VERSION ""

NS_ :

BS_:

BU_: HVC INV MOBO RPI SET VCU

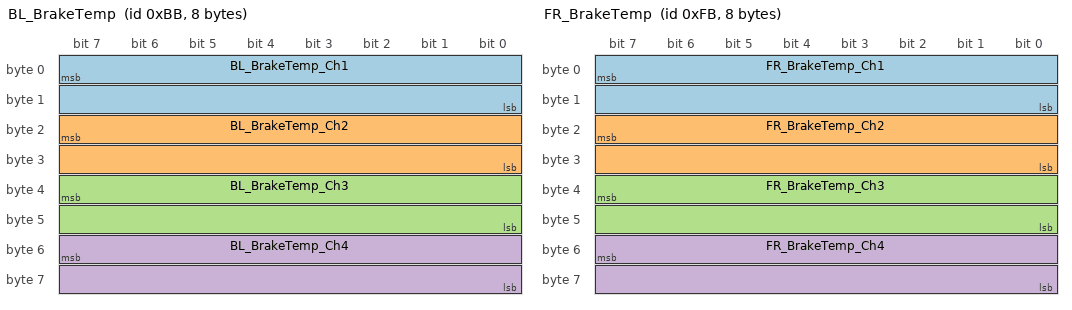
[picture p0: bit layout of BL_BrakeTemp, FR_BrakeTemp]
BO_ 187 BL_BrakeTemp: 8 BL
 SG_ BL_BrakeTemp_Ch1 : 7|16@0+ (0.1,-100.0) [-1000.0|1000.0] "C" Vector__XXX
 SG_ BL_BrakeTemp_Ch2 : 23|16@0+ (0.1,-100.0) [-1000.0|1000.0] "C" Vector__XXX
 SG_ BL_BrakeTemp_Ch3 : 39|16@0+ (0.1,-100.0) [-1000.0|1000.0] "C" Vector__XXX
 SG_ BL_BrakeTemp_Ch4 : 55|16@0+ (0.1,-100.0) [-1000.0|1000.0] "C" Vector__XXX

BO_ 251 FR_BrakeTemp: 8 FR
 SG_ FR_BrakeTemp_Ch1 : 7|16@0+ (0.1,-100.0) [-1000.0|1000.0] "C" Vector__XXX
 SG_ FR_BrakeTemp_Ch2 : 23|16@0+ (0.1,-100.0) [-1000.0|1000.0] "C" Vector__XXX
 SG_ FR_BrakeTemp_Ch3 : 39|16@0+ (0.1,-100.0) [-1000.0|1000.0] "C" Vector__XXX
 SG_ FR_BrakeTemp_Ch4 : 55|16@0+ (0.1,-100.0) [-1000.0|1000.0] "C" Vector__XXX

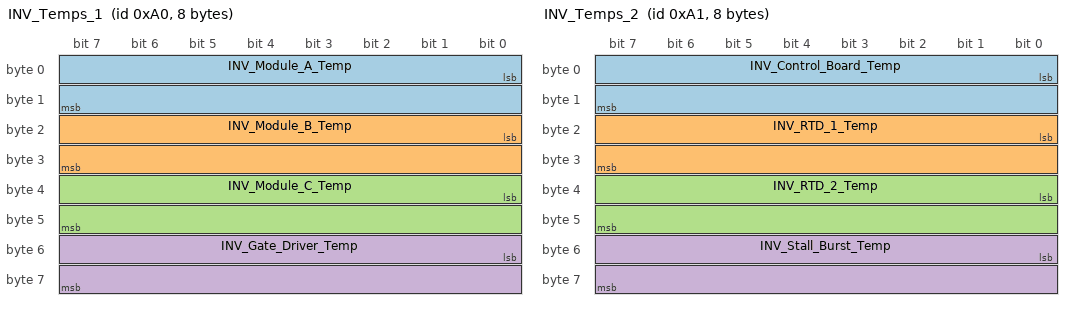
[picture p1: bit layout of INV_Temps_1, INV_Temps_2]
BO_ 160 INV_Temps_1: 8 INV
 SG_ INV_Module_A_Temp : 0|16@1- (0.1,0.0) [-1000.0|1000.0] "C" Vector__XXX
 SG_ INV_Module_B_Temp : 16|16@1- (0.1,0.0) [-1000.0|1000.0] "C" Vector__XXX
 SG_ INV_Module_C_Temp : 32|16@1- (0.1,0.0) [-1000.0|1000.0] "C" Vector__XXX
 SG_ INV_Gate_Driver_Temp : 48|16@1- (0.1,0.0) [-1000.0|1000.0] "C" Vector__XXX

BO_ 161 INV_Temps_2: 8 INV
 SG_ INV_Control_Board_Temp : 0|16@1- (0.1,0.0) [-1000.0|1000.0] "C" Vector__XXX
 SG_ INV_RTD_1_Temp : 16|16@1- (0.1,0.0) [-1000.0|1000.0] "C" Vector__XXX
 SG_ INV_RTD_2_Temp : 32|16@1- (0.1,0.0) [-1000.0|1000.0] "C" Vector__XXX
 SG_ INV_Stall_Burst_Temp : 48|16@1- (0.1,0.0) [-1000.0|1000.0] "C" Vector__XXX

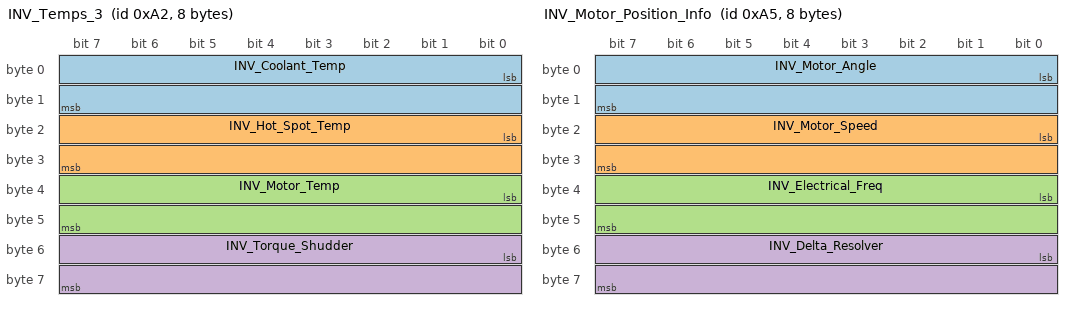
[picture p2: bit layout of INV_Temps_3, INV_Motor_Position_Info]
BO_ 162 INV_Temps_3: 8 INV
 SG_ INV_Coolant_Temp : 0|16@1- (0.1,0.0) [-1000.0|1000.0] "C" Vector__XXX
 SG_ INV_Hot_Spot_Temp : 16|16@1- (0.1,0.0) [-1000.0|1000.0] "C" Vector__XXX
 SG_ INV_Motor_Temp : 32|16@1- (0.1,0.0) [-1000.0|1000.0] "C" Vector__XXX
 SG_ INV_Torque_Shudder : 48|16@1- (0.1,0.0) [-230.0|230.0] "Nm" Vector__XXX

BO_ 165 INV_Motor_Position_Info: 8 INV
 SG_ INV_Motor_Angle : 0|16@1- (0.1,0.0) [-360.0|360.0] "deg" Vector__XXX
 SG_ INV_Motor_Speed : 16|16@1- (1.0,0.0) [-6000.0|6000.0] "RPM" Vector__XXX
 SG_ INV_Electrical_Freq : 32|16@1- (0.1,0.0) [-30000.0|30000.0] "Hz" Vector__XXX
 SG_ INV_Delta_Resolver : 48|16@1- (0.1,0.0) [-360.0|360.0] "deg" Vector__XXX

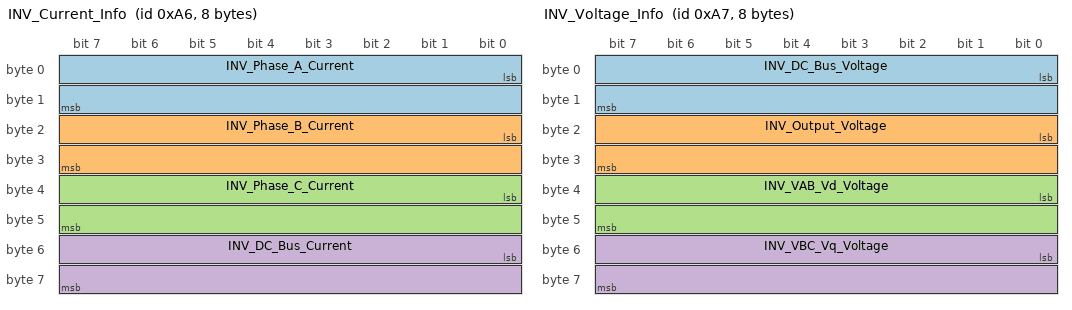
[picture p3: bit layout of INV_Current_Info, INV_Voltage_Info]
BO_ 166 INV_Current_Info: 8 INV
 SG_ INV_Phase_A_Current : 0|16@1- (0.1,0.0) [-1000.0|1000.0] "A" Vector__XXX
 SG_ INV_Phase_B_Current : 16|16@1- (0.1,0.0) [-1000.0|1000.0] "A" Vector__XXX
 SG_ INV_Phase_C_Current : 32|16@1- (0.1,0.0) [-1000.0|1000.0] "A" Vector__XXX
 SG_ INV_DC_Bus_Current : 48|16@1- (0.1,0.0) [-1000.0|1000.0] "A" Vector__XXX

BO_ 167 INV_Voltage_Info: 8 INV
 SG_ INV_DC_Bus_Voltage : 0|16@1- (0.1,0.0) [-1000.0|1000.0] "V" Vector__XXX
 SG_ INV_Output_Voltage : 16|16@1- (0.1,0.0) [-1000.0|1000.0] "V" Vector__XXX
 SG_ INV_VAB_Vd_Voltage : 32|16@1- (0.1,0.0) [-1000.0|1000.0] "V" Vector__XXX
 SG_ INV_VBC_Vq_Voltage : 48|16@1- (0.1,0.0) [-1000.0|1000.0] "V" Vector__XXX

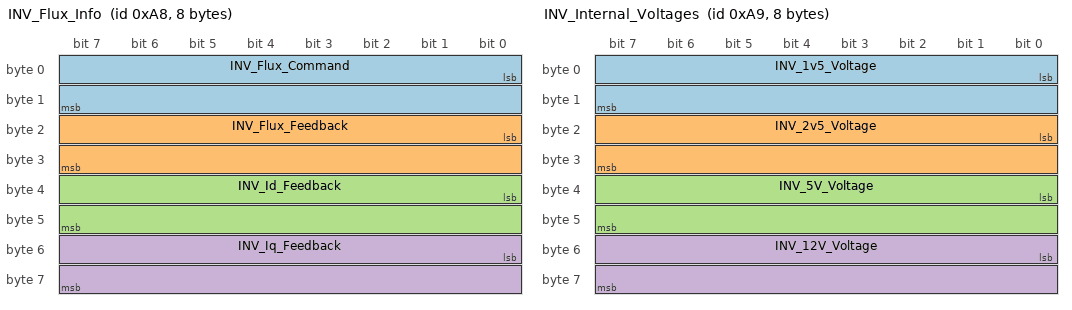
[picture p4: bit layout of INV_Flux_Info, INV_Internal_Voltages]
BO_ 168 INV_Flux_Info: 8 INV
 SG_ INV_Flux_Command : 0|16@1- (0.001,0.0) [-32.0|32.0] "Webers" Vector__XXX
 SG_ INV_Flux_Feedback : 16|16@1- (0.001,0.0) [-32.0|32.0] "Webers" Vector__XXX
 SG_ INV_Id_Feedback : 32|16@1- (0.1,0.0) [-1000.0|1000.0] "A" Vector__XXX
 SG_ INV_Iq_Feedback : 48|16@1- (0.1,0.0) [-1000.0|1000.0] "A" Vector__XXX

BO_ 169 INV_Internal_Voltages: 8 INV
 SG_ INV_1v5_Voltage : 0|16@1- (0.01,0.0) [-1000.0|1000.0] "V" Vector__XXX
 SG_ INV_2v5_Voltage : 16|16@1- (0.01,0.0) [-1000.0|1000.0] "V" Vector__XXX
 SG_ INV_5V_Voltage : 32|16@1- (0.01,0.0) [-1000.0|1000.0] "V" Vector__XXX
 SG_ INV_12V_Voltage : 48|16@1- (0.01,0.0) [-1000.0|1000.0] "V" Vector__XXX

BO_ 171 INV_Fault_Codes: 8 INV
 SG_ INV_Post_Fault_Lo : 0|16@1+ (1.0,0.0) [0.0|65535.0] "" Vector__XXX
 SG_ INV_Post_Fault_Hi : 16|16@1+ (1.0,0.0) [0.0|65535.0] "" Vector__XXX
 SG_ INV_Fault_Motor_Overspeed : 32|1@1+ (1.0,0.0) [0.0|1.0] "" Vector__XXX
 SG_ INV_Fault_Overcurrent : 33|1@1+ (1.0,0.0) [0.0|1.0] "" Vector__XXX
 SG_ INV_Fault_Overvoltage : 34|1@1+ (1.0,0.0) [0.0|1.0] "" Vector__XXX
 SG_ INV_Fault_Inverter_Overtemp : 35|1@1+ (1.0,0.0) [0.0|1.0] "" Vector__XXX
 SG_ INV_Fault_Accel_Input_Shorted : 36|1@1+ (1.0,0.0) [0.0|1.0] "" Vector__XXX
 SG_ INV_Fault_Accel_Input_Open : 37|1@1+ (1.0,0.0) [0.0|1.0] "" Vector__XXX
 SG_ INV_Fault_Direction_Cmd : 38|1@1+ (1.0,0.0) [0.0|1.0] "" Vector__XXX
 SG_ INV_Fault_Response_Timeout : 39|1@1+ (1.0,0.0) [0.0|1.0] "" Vector__XXX
 SG_ INV_Fault_HW_Gate : 40|1@1+ (1.0,0.0) [0.0|1.0] "" Vector__XXX
 SG_ INV_Fault_HW_Overcurrent : 41|1@1+ (1.0,0.0) [0.0|1.0] "" Vector__XXX
 SG_ INV_Fault_Undervoltage : 42|1@1+ (1.0,0.0) [0.0|1.0] "" Vector__XXX
 SG_ INV_Fault_Cmd_Msg_Lost : 43|1@1+ (1.0,0.0) [0.0|1.0] "" Vector__XXX
 SG_ INV_Fault_Motor_Overtemp : 44|1@1+ (1.0,0.0) [0.0|1.0] "" Vector__XXX
 SG_ INV_Fault_Brake_Input_Shorted : 48|1@1+ (1.0,0.0) [0.0|1.0] "" Vector__XXX
 SG_ INV_Fault_Brake_Input_Open : 49|1@1+ (1.0,0.0) [0.0|1.0] "" Vector__XXX
 SG_ INV_Fault_Module_A_Overtemp : 50|1@1+ (1.0,0.0) [0.0|1.0] "" Vector__XXX
 SG_ INV_Fault_Module_B_Overtemp : 51|1@1+ (1.0,0.0) [0.0|1.0] "" Vector__XXX
 SG_ INV_Fault_Module_C_Overtemp : 52|1@1+ (1.0,0.0) [0.0|1.0] "" Vector__XXX
 SG_ INV_Fault_PCB_Overtemp : 53|1@1+ (1.0,0.0) [0.0|1.0] "" Vector__XXX
 SG_ INV_Fault_Board_1_Overtemp : 54|1@1+ (1.0,0.0) [0.0|1.0] "" Vector__XXX
 SG_ INV_Fault_Board_2_Overtemp : 55|1@1+ (1.0,0.0) [0.0|1.0] "" Vector__XXX
 SG_ INV_Fault_Board_3_Overtemp : 56|1@1+ (1.0,0.0) [0.0|1.0] "" Vector__XXX
 SG_ INV_Fault_Curr_Sensor_Fault : 57|1@1+ (1.0,0.0) [0.0|1.0] "" Vector__XXX
 SG_ INV_Fault_Gate_Overvoltage : 58|1@1+ (1.0,0.0) [0.0|1.0] "" Vector__XXX
 SG_ INV_Fault_DC_Bus_Overvoltage : 60|1@1+ (1.0,0.0) [0.0|1.0] "" Vector__XXX
 SG_ INV_Fault_Resolver_Not_Cnctd : 62|1@1+ (1.0,0.0) [0.0|1.0] "" Vector__XXX

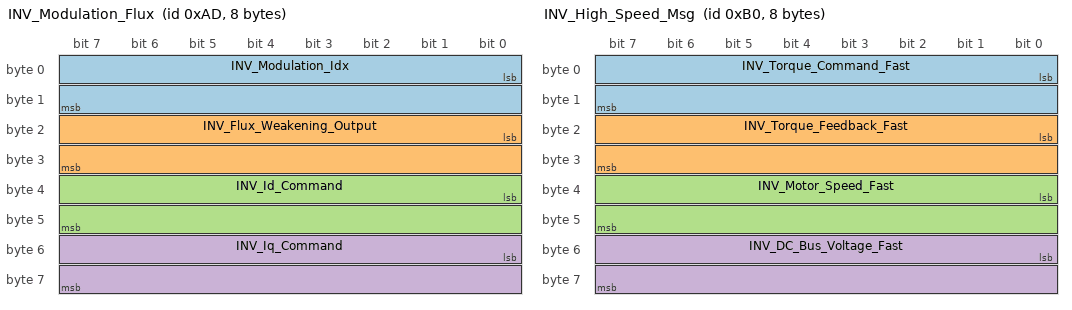
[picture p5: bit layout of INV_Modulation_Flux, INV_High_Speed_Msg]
BO_ 173 INV_Modulation_Flux: 8 INV
 SG_ INV_Modulation_Idx : 0|16@1+ (1.0,0.0) [0.0|65535.0] "" Vector__XXX
 SG_ INV_Flux_Weakening_Output : 16|16@1- (0.1,0.0) [-1000.0|1000.0] "A" Vector__XXX
 SG_ INV_Id_Command : 32|16@1- (0.1,0.0) [-1000.0|1000.0] "A" Vector__XXX
 SG_ INV_Iq_Command : 48|16@1- (0.1,0.0) [-1000.0|1000.0] "A" Vector__XXX

BO_ 176 INV_High_Speed_Msg: 8 INV
 SG_ INV_Torque_Command_Fast : 0|16@1- (0.1,0.0) [-230.0|230.0] "Nm" Vector__XXX
 SG_ INV_Torque_Feedback_Fast : 16|16@1- (0.1,0.0) [-230.0|230.0] "Nm" Vector__XXX
 SG_ INV_Motor_Speed_Fast : 32|16@1- (1.0,0.0) [-6000.0|6000.0] "RPM" Vector__XXX
 SG_ INV_DC_Bus_Voltage_Fast : 48|16@1- (0.1,0.0) [-1000.0|1000.0] "V" Vector__XXX

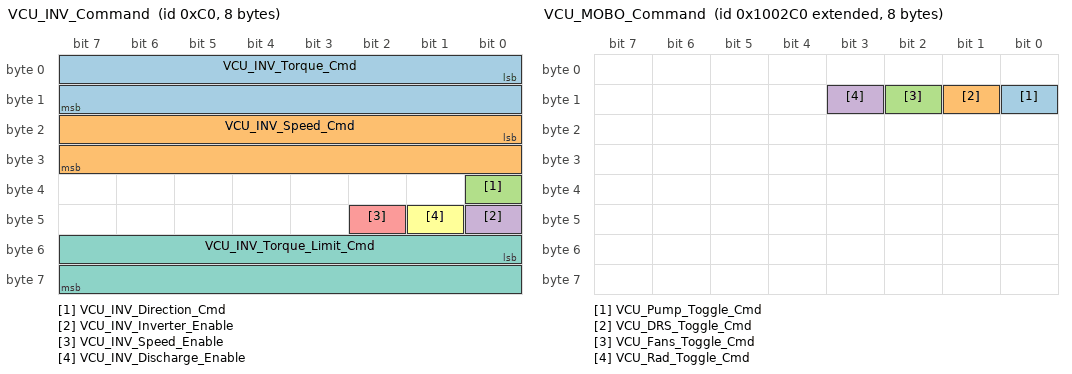
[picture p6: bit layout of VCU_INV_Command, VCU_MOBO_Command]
BO_ 192 VCU_INV_Command: 8 VCU
 SG_ VCU_INV_Torque_Cmd : 0|16@1- (0.1,0.0) [-230.0|230.0] "Nm" Vector__XXX
 SG_ VCU_INV_Speed_Cmd : 16|16@1- (1.0,0.0) [-6000.0|6000.0] "RPM" Vector__XXX
 SG_ VCU_INV_Direction_Cmd : 32|1@1+ (1.0,0.0) [0.0|1.0] "" Vector__XXX
 SG_ VCU_INV_Inverter_Enable : 40|1@1+ (1.0,0.0) [0.0|1.0] "" Vector__XXX
 SG_ VCU_INV_Speed_Enable : 42|1@1+ (1.0,0.0) [0.0|1.0] "" Vector__XXX
 SG_ VCU_INV_Discharge_Enable : 41|1@1+ (1.0,0.0) [0.0|1.0] "" Vector__XXX
 SG_ VCU_INV_Torque_Limit_Cmd : 48|16@1- (0.1,0.0) [-230.0|230.0] "Nm" Vector__XXX

BO_ 2147483855 SET_VCU_Config: 8 SET
 SG_ SET_VCU_Select M : 0|8@1+ (1.0,0.0) [0.0|255.0] "" Vector__XXX
 SG_ SET_VCU_Max_Torque m0 : 8|16@1- (0.1,0.0) [-230.0|230.0] "Nm" Vector__XXX
 SG_ SET_VCU_Motor_Direction m1 : 8|1@1+ (1.0,0.0) [0.0|1.0] "" Vector__XXX
 SG_ SET_VCU_Regen_Enabled m2 : 8|1@1+ (1.0,0.0) [0.0|1.0] "" Vector__XXX

BO_ 2147483867 HVC_VREF_Debug: 8 HVC
 SG_ HVC_VREF_mV : 16|32@1+ (1.0,0.0) [0.0|10000.0] "mV" Vector__XXX
 SG_ HVC_VREFINT_ADC : 0|16@1+ (1.0,0.0) [0.0|65535.0] "" Vector__XXX

BO_ 2148532928 VCU_MOBO_Command: 8 VCU
 SG_ VCU_Pump_Toggle_Cmd : 8|1@1+ (1.0,0.0) [0.0|1.0] "" Vector__XXX
 SG_ VCU_DRS_Toggle_Cmd : 9|1@1+ (1.0,0.0) [0.0|1.0] "" Vector__XXX
 SG_ VCU_Fans_Toggle_Cmd : 10|1@1+ (1.0,0.0) [0.0|1.0] "" Vector__XXX
 SG_ VCU_Rad_Toggle_Cmd : 11|1@1+ (1.0,0.0) [0.0|1.0] "" Vector__XXX

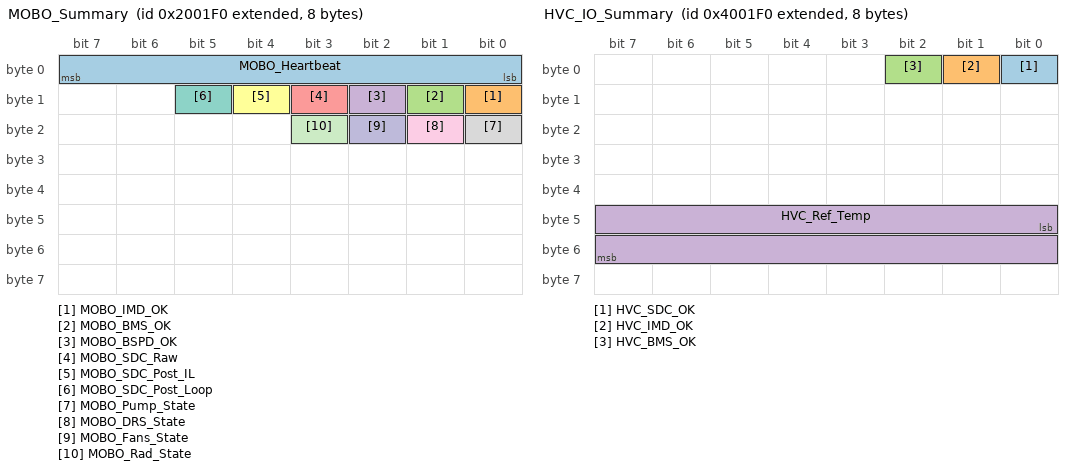
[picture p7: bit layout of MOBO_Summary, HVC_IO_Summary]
BO_ 2149581296 MOBO_Summary: 8 MOBO
 SG_ MOBO_Heartbeat : 0|8@1+ (1.0,0.0) [0.0|255.0] "" Vector__XXX
 SG_ MOBO_IMD_OK : 8|1@1+ (1.0,0.0) [0.0|1.0] "" Vector__XXX
 SG_ MOBO_BMS_OK : 9|1@1+ (1.0,0.0) [0.0|1.0] "" Vector__XXX
 SG_ MOBO_BSPD_OK : 10|1@1+ (1.0,0.0) [0.0|1.0] "" Vector__XXX
 SG_ MOBO_SDC_Raw : 11|1@1+ (1.0,0.0) [0.0|1.0] "" Vector__XXX
 SG_ MOBO_SDC_Post_IL : 12|1@1+ (1.0,0.0) [0.0|1.0] "" Vector__XXX
 SG_ MOBO_SDC_Post_Loop : 13|1@1+ (1.0,0.0) [0.0|1.0] "" Vector__XXX
 SG_ MOBO_Pump_State : 16|1@1+ (1.0,0.0) [0.0|1.0] "" Vector__XXX
 SG_ MOBO_DRS_State : 17|1@1+ (1.0,0.0) [0.0|1.0] "" Vector__XXX
 SG_ MOBO_Fans_State : 18|1@1+ (1.0,0.0) [0.0|1.0] "" Vector__XXX
 SG_ MOBO_Rad_State : 19|1@1+ (1.0,0.0) [0.0|1.0] "" Vector__XXX

BO_ 2151678448 HVC_IO_Summary: 8 HVC
 SG_ HVC_SDC_OK : 0|1@1+ (1.0,0.0) [0.0|1.0] "" Vector__XXX
 SG_ HVC_IMD_OK : 1|1@1+ (1.0,0.0) [0.0|1.0] "" Vector__XXX
 SG_ HVC_BMS_OK : 2|1@1+ (1.0,0.0) [0.0|1.0] "" Vector__XXX
 SG_ HVC_Ref_Temp : 40|16@1- (0.01,0.0) [-327.68|327.67] "C" Vector__XXX

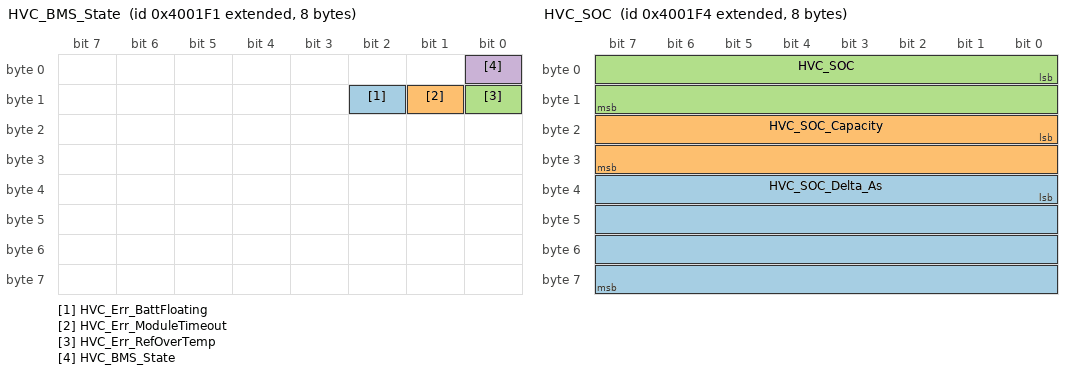
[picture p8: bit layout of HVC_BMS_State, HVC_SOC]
BO_ 2151678449 HVC_BMS_State: 8 HVC
 SG_ HVC_Err_BattFloating : 10|1@1+ (1.0,0.0) [0.0|1.0] "" Vector__XXX
 SG_ HVC_Err_ModuleTimeout : 9|1@1+ (1.0,0.0) [0.0|1.0] "" Vector__XXX
 SG_ HVC_Err_RefOverTemp : 8|1@1+ (1.0,0.0) [0.0|1.0] "" Vector__XXX
 SG_ HVC_BMS_State : 0|1@1+ (1.0,0.0) [0.0|1.0] "" Vector__XXX

BO_ 2151678451 HVC_IO_Current: 8 HVC
 SG_ HVC_Pack_Current_Hi : 32|32@1- (0.001,0.0) [-1000.0|1000.0] "A" Vector__XXX
 SG_ HVC_Pack_Current_Lo : 0|32@1- (0.001,0.0) [-1000.0|1000.0] "A" Vector__XXX

BO_ 2151678452 HVC_SOC: 8 HVC
 SG_ HVC_SOC_Delta_As : 32|32@1- (1.0,0.0) [-2147483648.0|2147483647.0] "A*s" Vector__XXX
 SG_ HVC_SOC_Capacity : 16|16@1+ (1.0,0.0) [0.0|65535.0] "A*s" Vector__XXX
 SG_ HVC_SOC : 0|16@1+ (0.01,0.0) [0.0|100.0] "%" Vector__XXX

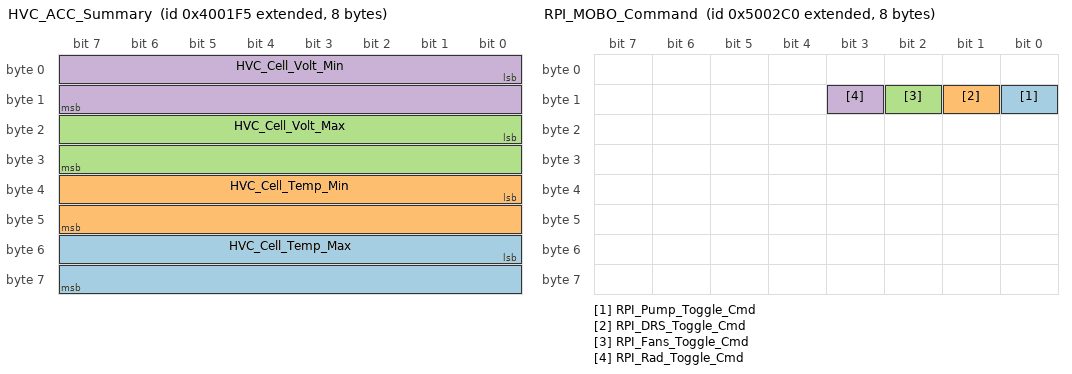
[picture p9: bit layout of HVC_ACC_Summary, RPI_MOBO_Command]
BO_ 2151678453 HVC_ACC_Summary: 8 HVC
 SG_ HVC_Cell_Temp_Max : 48|16@1- (0.1,0.0) [-1000.0|1000.0] "C" Vector__XXX
 SG_ HVC_Cell_Temp_Min : 32|16@1- (0.1,0.0) [-1000.0|1000.0] "C" Vector__XXX
 SG_ HVC_Cell_Volt_Max : 16|16@1+ (1.0,0.0) [0.0|10000.0] "mV" Vector__XXX
 SG_ HVC_Cell_Volt_Min : 0|16@1+ (1.0,0.0) [0.0|10000.0] "mV" Vector__XXX

BO_ 2151678455 HVC_IO_VSense: 8 HVC
 SG_ HVC_INV_Voltage : 32|32@1- (0.001,0.0) [-1000.0|1000.0] "V" Vector__XXX
 SG_ HVC_Pack_Voltage : 0|32@1- (0.001,0.0) [-1000.0|1000.0] "V" Vector__XXX

BO_ 2152727232 RPI_MOBO_Command: 8 RPI
 SG_ RPI_Pump_Toggle_Cmd : 8|1@1+ (1.0,0.0) [0.0|1.0] "" Vector__XXX
 SG_ RPI_DRS_Toggle_Cmd : 9|1@1+ (1.0,0.0) [0.0|1.0] "" Vector__XXX
 SG_ RPI_Fans_Toggle_Cmd : 10|1@1+ (1.0,0.0) [0.0|1.0] "" Vector__XXX
 SG_ RPI_Rad_Toggle_Cmd : 11|1@1+ (1.0,0.0) [0.0|1.0] "" Vector__XXX

VAL_ 171 INV_Fault_Motor_Overspeed 0 "FALSE" 1 "TRUE" ;
VAL_ 171 INV_Fault_Overcurrent 0 "FALSE" 1 "TRUE" ;
VAL_ 171 INV_Fault_Overvoltage 0 "FALSE" 1 "TRUE" ;
VAL_ 171 INV_Fault_Inverter_Overtemp 0 "FALSE" 1 "TRUE" ;
VAL_ 171 INV_Fault_Accel_Input_Shorted 0 "FALSE" 1 "TRUE" ;
VAL_ 171 INV_Fault_Accel_Input_Open 0 "FALSE" 1 "TRUE" ;
VAL_ 171 INV_Fault_Direction_Cmd 0 "FALSE" 1 "TRUE" ;
VAL_ 171 INV_Fault_Response_Timeout 0 "FALSE" 1 "TRUE" ;
VAL_ 171 INV_Fault_HW_Gate 0 "FALSE" 1 "TRUE" ;
VAL_ 171 INV_Fault_HW_Overcurrent 0 "FALSE" 1 "TRUE" ;
VAL_ 171 INV_Fault_Undervoltage 0 "FALSE" 1 "TRUE" ;
VAL_ 171 INV_Fault_Cmd_Msg_Lost 0 "FALSE" 1 "TRUE" ;
VAL_ 171 INV_Fault_Motor_Overtemp 0 "FALSE" 1 "TRUE" ;
VAL_ 171 INV_Fault_Brake_Input_Shorted 0 "FALSE" 1 "TRUE" ;
VAL_ 171 INV_Fault_Brake_Input_Open 0 "FALSE" 1 "TRUE" ;
VAL_ 171 INV_Fault_Module_A_Overtemp 0 "FALSE" 1 "TRUE" ;
VAL_ 171 INV_Fault_Module_B_Overtemp 0 "FALSE" 1 "TRUE" ;
VAL_ 171 INV_Fault_Module_C_Overtemp 0 "FALSE" 1 "TRUE" ;
VAL_ 171 INV_Fault_PCB_Overtemp 0 "FALSE" 1 "TRUE" ;
VAL_ 171 INV_Fault_Board_1_Overtemp 0 "FALSE" 1 "TRUE" ;
VAL_ 171 INV_Fault_Board_2_Overtemp 0 "FALSE" 1 "TRUE" ;
VAL_ 171 INV_Fault_Board_3_Overtemp 0 "FALSE" 1 "TRUE" ;
VAL_ 171 INV_Fault_Curr_Sensor_Fault 0 "FALSE" 1 "TRUE" ;
VAL_ 171 INV_Fault_Gate_Overvoltage 0 "FALSE" 1 "TRUE" ;
VAL_ 171 INV_Fault_DC_Bus_Overvoltage 0 "FALSE" 1 "TRUE" ;
VAL_ 171 INV_Fault_Resolver_Not_Cnctd 0 "FALSE" 1 "TRUE" ;
VAL_ 192 VCU_INV_Direction_Cmd 0 "REVERSE" 1 "FORWARD" ;
VAL_ 192 VCU_INV_Inverter_Enable 0 "FALSE" 1 "TRUE" ;
VAL_ 192 VCU_INV_Speed_Enable 0 "FALSE" 1 "TRUE" ;
VAL_ 192 VCU_INV_Discharge_Enable 0 "FALSE" 1 "TRUE" ;
VAL_ 2147483855 SET_VCU_Select 0 "MAX_TORQUE" 1 "MOTOR_DIRECTION" 2 "REGEN_ENABLED" ;
VAL_ 2147483855 SET_VCU_Motor_Direction 0 "REVERSE" 1 "FORWARD" ;
VAL_ 2147483855 SET_VCU_Regen_Enabled 0 "FALSE" 1 "TRUE" ;
VAL_ 2148532928 VCU_Pump_Toggle_Cmd 0 "FALSE" 1 "TRUE" ;
VAL_ 2148532928 VCU_DRS_Toggle_Cmd 0 "FALSE" 1 "TRUE" ;
VAL_ 2148532928 VCU_Fans_Toggle_Cmd 0 "FALSE" 1 "TRUE" ;
VAL_ 2148532928 VCU_Rad_Toggle_Cmd 0 "FALSE" 1 "TRUE" ;
VAL_ 2149581296 MOBO_IMD_OK 0 "FALSE" 1 "TRUE" ;
VAL_ 2149581296 MOBO_BMS_OK 0 "FALSE" 1 "TRUE" ;
VAL_ 2149581296 MOBO_BSPD_OK 0 "FALSE" 1 "TRUE" ;
VAL_ 2149581296 MOBO_SDC_Raw 0 "FALSE" 1 "TRUE" ;
VAL_ 2149581296 MOBO_SDC_Post_IL 0 "FALSE" 1 "TRUE" ;
VAL_ 2149581296 MOBO_SDC_Post_Loop 0 "FALSE" 1 "TRUE" ;
VAL_ 2149581296 MOBO_Pump_State 0 "FALSE" 1 "TRUE" ;
VAL_ 2149581296 MOBO_DRS_State 0 "FALSE" 1 "TRUE" ;
VAL_ 2149581296 MOBO_Fans_State 0 "FALSE" 1 "TRUE" ;
VAL_ 2149581296 MOBO_Rad_State 0 "FALSE" 1 "TRUE" ;
VAL_ 2151678448 HVC_SDC_OK 0 "FALSE" 1 "TRUE" ;
VAL_ 2151678448 HVC_IMD_OK 0 "FALSE" 1 "TRUE" ;
VAL_ 2151678448 HVC_BMS_OK 0 "FALSE" 1 "TRUE" ;
VAL_ 2151678449 HVC_Err_BattFloating 0 "FALSE" 1 "TRUE" ;
VAL_ 2151678449 HVC_Err_ModuleTimeout 0 "FALSE" 1 "TRUE" ;
VAL_ 2151678449 HVC_Err_RefOverTemp 0 "FALSE" 1 "TRUE" ;
VAL_ 2151678449 HVC_BMS_State 0 "FALSE" 1 "TRUE" ;
VAL_ 2152727232 RPI_Pump_Toggle_Cmd 0 "FALSE" 1 "TRUE" ;
VAL_ 2152727232 RPI_DRS_Toggle_Cmd 0 "FALSE" 1 "TRUE" ;
VAL_ 2152727232 RPI_Fans_Toggle_Cmd 0 "FALSE" 1 "TRUE" ;
VAL_ 2152727232 RPI_Rad_Toggle_Cmd 0 "FALSE" 1 "TRUE" ;
